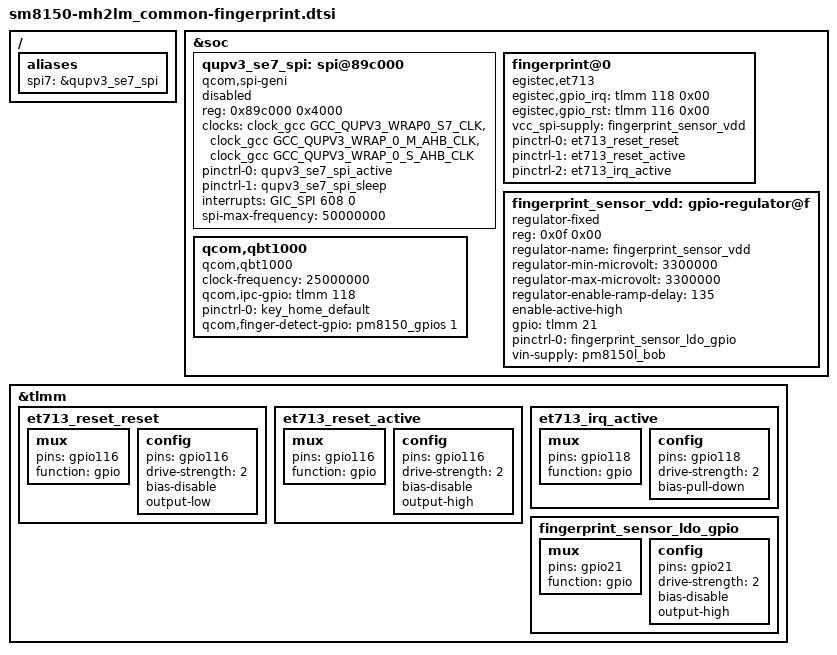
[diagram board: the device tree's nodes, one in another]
/*
 * Copyright (c) 2018, The Linux Foundation. All rights reserved.
 *
 * This program is free software; you can redistribute it and/or modify
 * it under the terms of the GNU General Public License version 2 and
 * only version 2 as published by the Free Software Foundation.
 *
 * This program is distributed in the hope that it will be useful,
 * but WITHOUT ANY WARRANTY; without even the implied warranty of
 * MERCHANTABILITY or FITNESS FOR A PARTICULAR PURPOSE. See the
 * GNU General Public License for more details.
 */
/{
	aliases {
		spi7 = &qupv3_se7_spi;
	};
/*
	reserved-memory {
		removed_regions: removed_regions@85800000 {
			reg = <0 0x85800000 0 0x2800000>;
		};
	};*/
};

&soc {
/*	qcom_seecom: qseecom@86600000 {
		reg = <0x86600000 0x1A00000>;
	};
*/
	/* PIN CONTROL for gf3208 */

	qupv3_se7_spi: spi@89c000 { /* QUP7 */
		compatible = "qcom,spi-geni";
		#address-cells = <1>;
		#size-cells = <0>;
		reg = <0x89c000 0x4000>;
		reg-names = "se_phys";
		clock-names = "se-clk", "m-ahb", "s-ahb";
		clocks = <&clock_gcc GCC_QUPV3_WRAP0_S7_CLK>,
			<&clock_gcc GCC_QUPV3_WRAP_0_M_AHB_CLK>,
			<&clock_gcc GCC_QUPV3_WRAP_0_S_AHB_CLK>;
		pinctrl-names = "default", "sleep";
		pinctrl-0 = <&qupv3_se7_spi_active>;
		pinctrl-1 = <&qupv3_se7_spi_sleep>;
		interrupts = <GIC_SPI 608 0>;
		spi-max-frequency = <50000000>;
		status = "disable";
	};
};
&soc{
	fingerprint@0 {
		compatible = "egistec,et713";

        
        egistec,gpio_irq = <&tlmm 118 0x00>;
        egistec,gpio_rst = <&tlmm 116 0x00>;
        vcc_spi-supply = <&fingerprint_sensor_vdd>;
		pinctrl-names = "et713_reset_reset",
						"et713_reset_active",
						"et713_irq_active";
		pinctrl-0 = <&et713_reset_reset>;
		pinctrl-1 = <&et713_reset_active>;
		pinctrl-2 = <&et713_irq_active>;

		status = "ok";
	};

	fingerprint_sensor_vdd: gpio-regulator@f {
		compatible = "regulator-fixed";
		reg = <0x0f 0x00>;
		regulator-name = "fingerprint_sensor_vdd";
		regulator-min-microvolt = <3300000>;
		regulator-max-microvolt = <3300000>;
		regulator-enable-ramp-delay = <135>; // TBD
		enable-active-high;
		gpio = <&tlmm 21 0>;
		pinctrl-names = "default";
		pinctrl-0 = <&fingerprint_sensor_ldo_gpio>;
		vin-supply = <&pm8150l_bob>;
	};

	qcom,qbt1000 {
		compatible = "qcom,qbt1000";
		clock-names = "core", "iface";
		clock-frequency = <25000000>;
		qcom,ipc-gpio = <&tlmm 118 0>;
		pinctrl-names = "default";
		pinctrl-0 = <&key_home_default>;
		qcom,finger-detect-gpio = <&pm8150_gpios 1 0>;
	};
};

&tlmm {
	et713_reset_reset: et713_reset_reset {
		mux {
			pins = "gpio116";
			function = "gpio";
		};
		config {
			pins = "gpio116";
			drive-strength = <2>;
			bias-disable;
			output-low;
		};
	};

	et713_reset_active: et713_reset_active {
		mux {
			pins = "gpio116";
			function = "gpio";
		};
		config {
			pins = "gpio116";
			drive-strength = <2>;
			bias-disable;
			output-high;
		};
	};

	et713_irq_active: et713_irq_active {
		mux {
			pins = "gpio118";
			function = "gpio";
		};
		config {
			pins = "gpio118";
			drive-strength = <2>;
			bias-pull-down;
		};
	};

	fingerprint_sensor_ldo_gpio: fingerprint_sensor_ldo_gpio { // et713_ldo_high
		mux {
			pins = "gpio21";
			function = "gpio";
		};
		config {
			pins = "gpio21";
			drive-strength = <2>;
			bias-disable;
			output-high;
		};
	};
};

